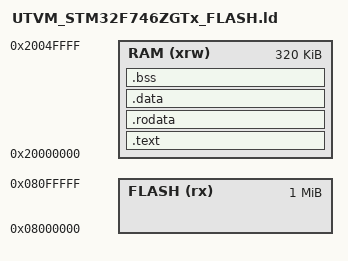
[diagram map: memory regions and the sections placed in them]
/*
*****************************************************************************
**

**  File        : LinkerScript.ld
**
**  Abstract    : Linker script for STM32F746ZGTx Device with
**                1024KByte FLASH, 320KByte RAM
**
**                Set heap size, stack size and stack location according
**                to application requirements.
**
**                Set memory bank area and size if external memory is used.
**
**  Target      : STMicroelectronics STM32
**
**
**  Distribution: The file is distributed as is, without any warranty
**                of any kind.
**
**  (c)Copyright Ac6.
**  You may use this file as-is or modify it according to the needs of your
**  project. Distribution of this file (unmodified or modified) is not
**  permitted. Ac6 permit registered System Workbench for MCU users the
**  rights to distribute the assembled, compiled & linked contents of this
**  file as part of an application binary file, provided that it is built
**  using the System Workbench for MCU toolchain.
**
*****************************************************************************
*/

/* Entry Point */
ENTRY(Reset_Handler)

/* Highest address of the user mode stack */
_estack = 0x20050000;   /* end of RAM */

/* Specify the memory areas */
MEMORY
{
RAM (xrw)      : ORIGIN = 0x20000000, LENGTH = 320K
FLASH (rx)     : ORIGIN = 0x8000000, LENGTH = 1024K
}

/* Define output sections */
SECTIONS
{
  .text :
  {
    . = ALIGN(4);
    *(.text)           /* .text sections (code) */
    *(.text*)          /* .text* sections (code) */
    . = ALIGN(4);
  } >RAM

  .rodata :
  {
    . = ALIGN(4);
    *(.rodata)         /* .rodata sections (constants, strings, etc.) */
    *(.rodata*)        /* .rodata* sections (constants, strings, etc.) */
    . = ALIGN(4);
  } >RAM

  .data :
  {
    . = ALIGN(4);
    *(.data)           /* .data sections */
    *(.data*)          /* .data* sections */
    . = ALIGN(4);
  } >RAM

  /* Uninitialized data section */
  . = ALIGN(4);
  .bss :
  {
    *(.bss)
    *(.bss*)
    . = ALIGN(4);
  } >RAM

  /* Remove information from the standard libraries */
  /DISCARD/ :
  {
    libc.a ( * )
    libm.a ( * )
    libgcc.a ( * )
  }
}

